# DCB register map
Vendor: Texas Instruments
Peripheral module from a debugger description file (folder UCD3138R064RSM).
Registers are 32-bit, access per field, reset 0x0 unless marked. A register's access mark holds for its fields unless they carry their own. Offsets are as the file gives them; lines under a group give offsets from that group; [hi:lo] are bit positions; {n}, {i} and the like mark numbered series; 'fields as' and 'values as' point back to an identical list; <NAME> marks a mode.

## DCB
0x10 DHCSR — Controls halting debug
  [26] S_RESTART_ST ro — Indicates the PE has processed a request to clear DHCSR.C_HALT to 0. That is, either a write to DHCSR that clears DHCSR.C_HALT from 1 to 0, or an External Restart Request
  [25] S_RESET_ST ro — Indicates whether the PE has been reset since the last read of the DHCSR
  [24] S_RETIRE_ST ro — Set to 1 every time the PE retires one of more instructions
  [23:21] RES0_1 ro — Reserved, RES0
  [20] S_SDE ro — Indicates whether Secure invasive debug is allowed
  [19] S_LOCKUP ro — Indicates whether the PE is in Lockup state
  [18] S_SLEEP ro — Indicates whether the PE is sleeping
  [17] S_HALT ro — Indicates whether the PE is in Debug state
  [31:16] DBGKEY wo — A debugger must write 0xA05F to this field to enable write access to the remaining bits, otherwise the PE ignores the write access
  [16] S_REGRDY ro — Handshake flag to transfers through the DCRDR
  [15:6] RES0_2 ro — Reserved, RES0
  [5] C_SNAPSTALL rw — Allow imprecise entry to Debug state
  [4] RES0_3 ro — Reserved, RES0
  [3] C_MASKINTS rw — When debug is enabled, the debugger can write to this bit to mask PendSV, SysTick and external configurable interrupts
  [2] C_STEP rw — Enable single instruction step
  [1] C_HALT rw — PE enter Debug state halt request
  [0] C_DEBUGEN rw — Enable Halting debug
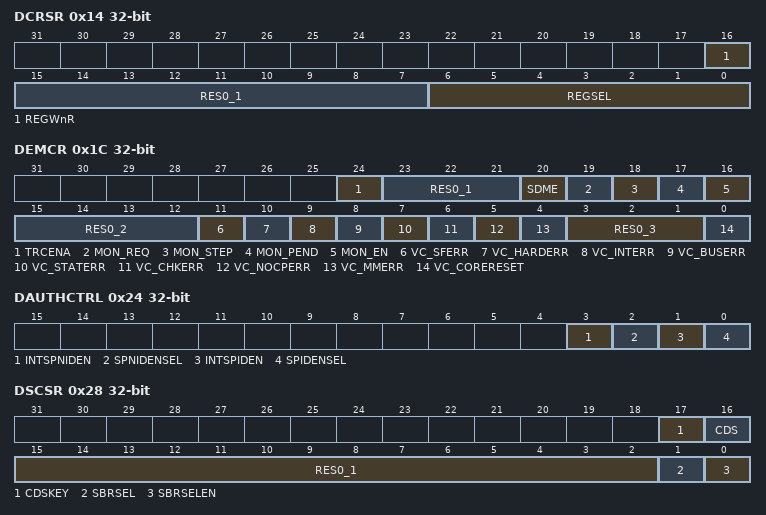
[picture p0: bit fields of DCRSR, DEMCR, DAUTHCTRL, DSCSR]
0x14 DCRSR — With the DCRDR, provides debug access to the general-purpose registers, special-purpose registers, and the FP extension registers. A write to the DCRSR specifies the register to transfer, whether the transfer is a read or write, and starts the transfer
  [16] REGWnR wo — Specifies the access type for the transfer
  [15:7] RES0_1 ro — Reserved, RES0
  [6:0] REGSEL wo — Specifies the general-purpose register, special-purpose register, or FP register to transfer
0x18 DCRDR rw — With the DCRSR, provides debug access to the general-purpose registers, special-purpose registers, and the FP Extension registers. If the Main Extension is implemented, it can also be used for message passing between an external debugger and a debug agent running on the PE
  [31:0] DBGTMP — Provides debug access for reading and writing the general-purpose registers, special-purpose registers, and Floating-point Extension registers
0x1C DEMCR — Manages vector catch behavior and DebugMonitor handling when debugging
  [24] TRCENA rw — Global enable for all DWT and ITM features
  [23:21] RES0_1 ro — Reserved, RES0
  [20] SDME ro — Indicates whether the DebugMonitor targets the Secure or the Non-secure state and whether debug events are allowed in Secure state
  [19] MON_REQ rw — DebugMonitor semaphore bit
  [18] MON_STEP rw — Enable DebugMonitor stepping
  [17] MON_PEND rw — Sets or clears the pending state of the DebugMonitor exception
  [16] MON_EN rw — Enable the DebugMonitor exception
  [15:12] RES0_2 ro — Reserved, RES0
  [11] VC_SFERR rw — SecureFault exception halting debug vector catch enable
  [10] VC_HARDERR rw — HardFault exception halting debug vector catch enable
  [9] VC_INTERR rw — Enable halting debug vector catch for faults during exception entry and return
  [8] VC_BUSERR rw — BusFault exception halting debug vector catch enable
  [7] VC_STATERR rw — Enable halting debug trap on a UsageFault exception caused by a state information error, for example an Undefined Instruction exception
  [6] VC_CHKERR rw — Enable halting debug trap on a UsageFault exception caused by a checking error, for example an alignment check error
  [5] VC_NOCPERR rw — Enable halting debug trap on a UsageFault caused by an access to a coprocessor
  [4] VC_MMERR rw — Enable halting debug trap on a MemManage exception
  [3:1] RES0_3 ro — Reserved, RES0
  [0] VC_CORERESET rw — Enable Reset Vector Catch. This causes a warm reset to halt a running system
0x24 DAUTHCTRL — This register allows the external authentication interface to be overridden from software.
  [3] INTSPNIDEN rw — Internal Secure non-invasive debug enable. Overrides the external Secure non-invasive debug authentication interface
  [2] SPNIDENSEL rw — Secure non-invasive debug enable select. Selects between DAUTHCTRL and the external authentication interface for control of Secure non-invasive debug
  [1] INTSPIDEN rw — Internal Secure invasive debug enable. Overrides the external Secure invasive debug authentication Interfaces.
  [0] SPIDENSEL rw — Secure invasive debug enable select. Selects between DAUTHCTRL and the external authentication interface for control of Secure invasive debug.
0x28 DSCSR — Provides control and status information for Secure debug
  [17] CDSKEY rw — Writes to the CDS bit are ignored unless CDSKEY is concurrently written to zero
  [16] CDS rw — This field indicates the current Security state of the processor
  [15:2] RES0_1 ro — Reserved, RES0
  [1] SBRSEL rw — If SBRSELEN is 1 this bit selects whether the Non-secure or the Secure version of the memory-mapped Banked registers are accessible to the debugger
  [0] SBRSELEN rw — Controls whether the SBRSEL field or the current Security state of the processor selects which version of the memory-mapped Banked registers are accessed to the debugger
